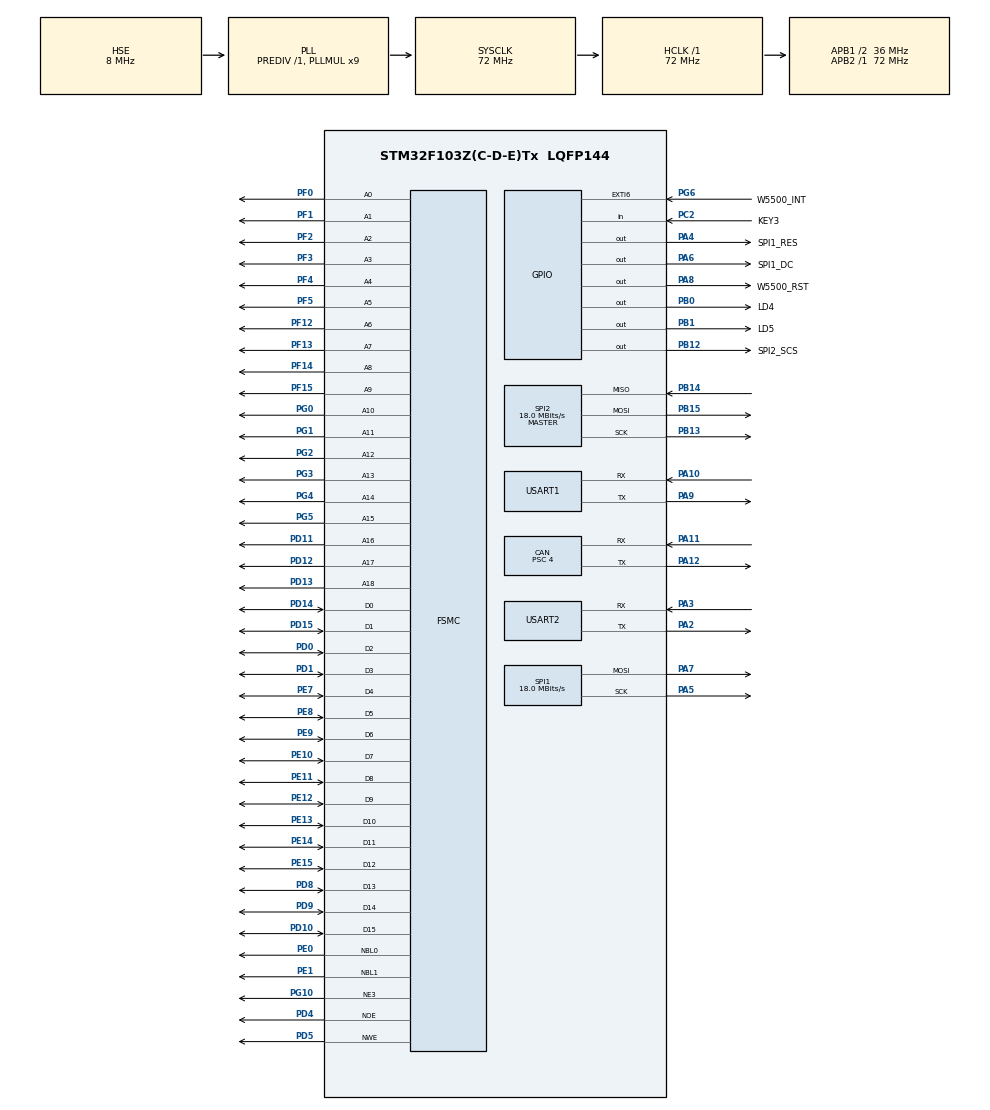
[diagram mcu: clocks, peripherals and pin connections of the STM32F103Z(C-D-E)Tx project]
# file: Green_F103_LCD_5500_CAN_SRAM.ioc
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CAN.BS1=CAN_BS1_9TQ
CAN.BS2=CAN_BS2_8TQ
CAN.CalculateTimeBit=2000
CAN.CalculateTimeQuantum=111.11111111111111
CAN.Prescaler=4
FSMC.AddressSetupTime1=0
FSMC.BusTurnAroundDuration1=0
FSMC.DataSetupTime1=4
FSMC.WriteOperation1=FSMC_WRITE_OPERATION_ENABLE
Mcu.Family=STM32F1
Mcu.Name=STM32F103Z(C-D-E)Tx
Mcu.Package=LQFP144
NVIC.PriorityGroup=NVIC_PRIORITYGROUP_4
NVIC.USART1_IRQn=true\:0\:0\:false\:false\:true\:true\:true
NVIC.USART2_IRQn=true\:0\:0\:false\:false\:true\:true\:true
OSC_IN.Mode=HSE-External-Oscillator
OSC_IN.Signal=RCC_OSC_IN
OSC_OUT.Mode=HSE-External-Oscillator
OSC_OUT.Signal=RCC_OSC_OUT
PA10.Mode=Asynchronous
PA10.Signal=USART1_RX
PA11.Mode=Master
PA11.Signal=CAN_RX
PA12.Mode=Master
PA12.Signal=CAN_TX
PA13.Mode=Serial_Wire
PA13.Signal=SYS_JTMS-SWDIO
PA14.Mode=Serial_Wire
PA14.Signal=SYS_JTCK-SWCLK
PA2.Mode=Asynchronous
PA2.Signal=USART2_TX
PA3.Mode=Asynchronous
PA3.Signal=USART2_RX
PA4.GPIO_Label=SPI1_RES
PA4.GPIO_ModeDefaultOutputPP=GPIO_MODE_OUTPUT_PP
PA4.GPIO_PuPd=GPIO_NOPULL
PA4.GPIO_Speed=GPIO_SPEED_FREQ_HIGH
PA4.PinState=GPIO_PIN_SET
PA4.Signal=GPIO_Output
PA5.Mode=TX_Only_Simplex_Unidirect_Master
PA5.Signal=SPI1_SCK
PA6.GPIO_Label=SPI1_DC
PA6.GPIO_ModeDefaultOutputPP=GPIO_MODE_OUTPUT_PP
PA6.GPIO_PuPd=GPIO_NOPULL
PA6.GPIO_Speed=GPIO_SPEED_FREQ_HIGH
PA6.PinState=GPIO_PIN_SET
PA6.Signal=GPIO_Output
PA7.Mode=TX_Only_Simplex_Unidirect_Master
PA7.Signal=SPI1_MOSI
PA8.GPIO_Label=W5500_RST
PA8.GPIO_ModeDefaultOutputPP=GPIO_MODE_OUTPUT_PP
PA8.GPIO_PuPd=GPIO_NOPULL
PA8.GPIO_Speed=GPIO_SPEED_FREQ_HIGH
PA8.PinState=GPIO_PIN_SET
PA8.Signal=GPIO_Output
PA9.Mode=Asynchronous
PA9.Signal=USART1_TX
PB0.GPIO_Label=LD4
PB0.GPIO_ModeDefaultOutputPP=GPIO_MODE_OUTPUT_PP
PB0.GPIO_PuPd=GPIO_NOPULL
PB0.GPIO_Speed=GPIO_SPEED_FREQ_HIGH
PB0.PinState=GPIO_PIN_SET
PB0.Signal=GPIO_Output
PB1.GPIO_Label=LD5
PB1.GPIO_ModeDefaultOutputPP=GPIO_MODE_OUTPUT_PP
PB1.GPIO_PuPd=GPIO_NOPULL
PB1.GPIO_Speed=GPIO_SPEED_FREQ_HIGH
PB1.PinState=GPIO_PIN_SET
PB1.Signal=GPIO_Output
PB12.GPIO_Label=SPI2_SCS
PB12.GPIO_ModeDefaultOutputPP=GPIO_MODE_OUTPUT_PP
PB12.GPIO_PuPd=GPIO_NOPULL
PB12.GPIO_Speed=GPIO_SPEED_FREQ_HIGH
PB12.PinState=GPIO_PIN_SET
PB12.Signal=GPIO_Output
PB13.Mode=Full_Duplex_Master
PB13.Signal=SPI2_SCK
PB14.Mode=Full_Duplex_Master
PB14.Signal=SPI2_MISO
PB15.Mode=Full_Duplex_Master
PB15.Signal=SPI2_MOSI
PC14-OSC32_IN.Mode=LSE-External-Oscillator
PC14-OSC32_IN.Signal=RCC_OSC32_IN
PC15-OSC32_OUT.Mode=LSE-External-Oscillator
PC15-OSC32_OUT.Signal=RCC_OSC32_OUT
PC2.GPIO_Label=KEY3
PC2.GPIO_PuPd=GPIO_PULLUP
PC2.Signal=GPIO_Input
PD0.Signal=FSMC_D2_DA2
PD1.Signal=FSMC_D3_DA3
PD10.Signal=FSMC_D15_DA15
PD11.Signal=FSMC_A16_CLE
PD12.Signal=FSMC_A17_ALE
PD13.Signal=FSMC_A18
PD14.Signal=FSMC_D0_DA0
PD15.Signal=FSMC_D1_DA1
PD4.Signal=FSMC_NOE
PD5.Signal=FSMC_NWE
PD8.Signal=FSMC_D13_DA13
PD9.Signal=FSMC_D14_DA14
PE0.Signal=FSMC_NBL0
PE1.Signal=FSMC_NBL1
PE10.Signal=FSMC_D7_DA7
PE11.Signal=FSMC_D8_DA8
PE12.Signal=FSMC_D9_DA9
PE13.Signal=FSMC_D10_DA10
PE14.Signal=FSMC_D11_DA11
PE15.Signal=FSMC_D12_DA12
PE7.Signal=FSMC_D4_DA4
PE8.Signal=FSMC_D5_DA5
PE9.Signal=FSMC_D6_DA6
PF0.Signal=FSMC_A0
PF1.Signal=FSMC_A1
PF12.Signal=FSMC_A6
PF13.Signal=FSMC_A7
PF14.Signal=FSMC_A8
PF15.Signal=FSMC_A9
PF2.Signal=FSMC_A2
PF3.Signal=FSMC_A3
PF4.Signal=FSMC_A4
PF5.Signal=FSMC_A5
PG0.Signal=FSMC_A10
PG1.Signal=FSMC_A11
PG10.Mode=NorPsramChipSelect3_1
PG10.Signal=FSMC_NE3
PG2.Signal=FSMC_A12
PG3.Signal=FSMC_A13
PG4.Signal=FSMC_A14
PG5.Signal=FSMC_A15
PG6.GPIO_Label=W5500_INT
PG6.Signal=GPXTI6
ProjectManager.HeapSize=0x800
ProjectManager.StackSize=0x800
ProjectManager.TargetToolchain=MDK-ARM V5
RCC.AHBFreq_Value=72000000
RCC.APB1CLKDivider=RCC_HCLK_DIV2
RCC.APB1Freq_Value=36000000
RCC.APB1TimFreq_Value=72000000
RCC.APB2Freq_Value=72000000
RCC.APB2TimFreq_Value=72000000
RCC.HCLKFreq_Value=72000000
RCC.PLLMUL=RCC_PLL_MUL9
RCC.PLLSourceVirtual=RCC_PLLSOURCE_HSE
RCC.SYSCLKFreq_VALUE=72000000
RCC.SYSCLKSource=RCC_SYSCLKSOURCE_PLLCLK
RCC.USBFreq_Value=72000000
SH.FSMC_A0.0=FSMC_A0,19b-a1
SH.FSMC_A1.0=FSMC_A1,19b-a1
SH.FSMC_A10.0=FSMC_A10,19b-a1
SH.FSMC_A11.0=FSMC_A11,19b-a1
SH.FSMC_A12.0=FSMC_A12,19b-a1
SH.FSMC_A13.0=FSMC_A13,19b-a1
SH.FSMC_A14.0=FSMC_A14,19b-a1
SH.FSMC_A15.0=FSMC_A15,19b-a1
SH.FSMC_A16_CLE.0=FSMC_A16,19b-a1
SH.FSMC_A17_ALE.0=FSMC_A17,19b-a1
SH.FSMC_A18.0=FSMC_A18,19b-a1
SH.FSMC_A2.0=FSMC_A2,19b-a1
SH.FSMC_A3.0=FSMC_A3,19b-a1
SH.FSMC_A4.0=FSMC_A4,19b-a1
SH.FSMC_A5.0=FSMC_A5,19b-a1
SH.FSMC_A6.0=FSMC_A6,19b-a1
SH.FSMC_A7.0=FSMC_A7,19b-a1
SH.FSMC_A8.0=FSMC_A8,19b-a1
SH.FSMC_A9.0=FSMC_A9,19b-a1
SH.FSMC_D0_DA0.0=FSMC_D0,16b-d1
SH.FSMC_D10_DA10.0=FSMC_D10,16b-d1
SH.FSMC_D11_DA11.0=FSMC_D11,16b-d1
SH.FSMC_D12_DA12.0=FSMC_D12,16b-d1
SH.FSMC_D13_DA13.0=FSMC_D13,16b-d1
SH.FSMC_D14_DA14.0=FSMC_D14,16b-d1
SH.FSMC_D15_DA15.0=FSMC_D15,16b-d1
SH.FSMC_D1_DA1.0=FSMC_D1,16b-d1
SH.FSMC_D2_DA2.0=FSMC_D2,16b-d1
SH.FSMC_D3_DA3.0=FSMC_D3,16b-d1
SH.FSMC_D4_DA4.0=FSMC_D4,16b-d1
SH.FSMC_D5_DA5.0=FSMC_D5,16b-d1
SH.FSMC_D6_DA6.0=FSMC_D6,16b-d1
SH.FSMC_D7_DA7.0=FSMC_D7,16b-d1
SH.FSMC_D8_DA8.0=FSMC_D8,16b-d1
SH.FSMC_D9_DA9.0=FSMC_D9,16b-d1
SH.FSMC_NBL0.0=FSMC_NBL0,2ByteEnable1
SH.FSMC_NBL1.0=FSMC_NBL1,2ByteEnable1
SH.FSMC_NOE.0=FSMC_NOE,Sram1
SH.FSMC_NWE.0=FSMC_NWE,Sram1
SPI1.BaudRatePrescaler=SPI_BAUDRATEPRESCALER_4
SPI1.CLKPhase=SPI_PHASE_2EDGE
SPI1.CLKPolarity=SPI_POLARITY_HIGH
SPI1.CalculateBaudRate=18.0 MBits/s
SPI1.Direction=SPI_DIRECTION_2LINES
SPI1.Mode=SPI_MODE_MASTER
SPI1.VirtualType=VM_MASTER
SPI2.CLKPhase=SPI_PHASE_2EDGE
SPI2.CLKPolarity=SPI_POLARITY_HIGH
SPI2.CalculateBaudRate=18.0 MBits/s
SPI2.Direction=SPI_DIRECTION_2LINES
SPI2.Mode=SPI_MODE_MASTER
SPI2.VirtualType=VM_MASTER
USART1.VirtualMode=VM_ASYNC
USART2.VirtualMode=VM_ASYNC
board=custom

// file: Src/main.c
/* USER CODE BEGIN Header */
/**
  ******************************************************************************
  * @file           : main.c
  * @brief          : Main program body
  ******************************************************************************
  * @attention
  *
  * <h2><center>&copy; Copyright (c) 2019 STMicroelectronics.
  * All rights reserved.</center></h2>
  *
  * This software component is licensed by ST under BSD 3-Clause license,
  * the "License"; You may not use this file except in compliance with the
  * License. You may obtain a copy of the License at:
  *                        opensource.org/licenses/BSD-3-Clause
  *
  ******************************************************************************
  */
/* USER CODE END Header */

#include "main.h"

CAN_HandleTypeDef hcan;

SPI_HandleTypeDef hspi1;
SPI_HandleTypeDef hspi2;

UART_HandleTypeDef huart1;
UART_HandleTypeDef huart2;

SRAM_HandleTypeDef hsram1;

void SystemClock_Config(void);
static void MX_GPIO_Init(void);
static void MX_CAN_Init(void);
static void MX_FSMC_Init(void);
static void MX_SPI1_Init(void);
static void MX_SPI2_Init(void);
static void MX_USART1_UART_Init(void);
static void MX_USART2_UART_Init(void);

int main(void)
{

  /* MCU Configuration--------------------------------------------------------*/

  /* Reset of all peripherals, Initializes the Flash interface and the Systick. */
  HAL_Init();

  /* Configure the system clock */
  SystemClock_Config();

  /* Initialize all configured peripherals */
  MX_GPIO_Init();
  MX_CAN_Init();
  MX_FSMC_Init();
  MX_SPI1_Init();
  MX_SPI2_Init();
  MX_USART1_UART_Init();
  MX_USART2_UART_Init();
  /* USER CODE BEGIN 2 */
  u_main();
  /* USER CODE END 2 */

  /* Infinite loop */
  while (1)
  {

  }
}

void SystemClock_Config(void)
{
  RCC_OscInitTypeDef RCC_OscInitStruct = {0};
  RCC_ClkInitTypeDef RCC_ClkInitStruct = {0};

  /** Initializes the CPU, AHB and APB busses clocks
  */
  RCC_OscInitStruct.OscillatorType = RCC_OSCILLATORTYPE_HSE;
  RCC_OscInitStruct.HSEState = RCC_HSE_ON;
  RCC_OscInitStruct.HSEPredivValue = RCC_HSE_PREDIV_DIV1;
  RCC_OscInitStruct.HSIState = RCC_HSI_ON;
  RCC_OscInitStruct.PLL.PLLState = RCC_PLL_ON;
  RCC_OscInitStruct.PLL.PLLSource = RCC_PLLSOURCE_HSE;
  RCC_OscInitStruct.PLL.PLLMUL = RCC_PLL_MUL9;
  if (HAL_RCC_OscConfig(&RCC_OscInitStruct) != HAL_OK)
  {
    Error_Handler();
  }
  /** Initializes the CPU, AHB and APB busses clocks
  */
  RCC_ClkInitStruct.ClockType = RCC_CLOCKTYPE_HCLK|RCC_CLOCKTYPE_SYSCLK
                              |RCC_CLOCKTYPE_PCLK1|RCC_CLOCKTYPE_PCLK2;
  RCC_ClkInitStruct.SYSCLKSource = RCC_SYSCLKSOURCE_PLLCLK;
  RCC_ClkInitStruct.AHBCLKDivider = RCC_SYSCLK_DIV1;
  RCC_ClkInitStruct.APB1CLKDivider = RCC_HCLK_DIV2;
  RCC_ClkInitStruct.APB2CLKDivider = RCC_HCLK_DIV1;

  if (HAL_RCC_ClockConfig(&RCC_ClkInitStruct, FLASH_LATENCY_2) != HAL_OK)
  {
    Error_Handler();
  }
}

static void MX_CAN_Init(void)
{

  hcan.Instance = CAN1;
  hcan.Init.Prescaler = 4;
  hcan.Init.Mode = CAN_MODE_NORMAL;
  hcan.Init.SyncJumpWidth = CAN_SJW_1TQ;
  hcan.Init.TimeSeg1 = CAN_BS1_9TQ;
  hcan.Init.TimeSeg2 = CAN_BS2_8TQ;
  hcan.Init.TimeTriggeredMode = DISABLE;
  hcan.Init.AutoBusOff = DISABLE;
  hcan.Init.AutoWakeUp = DISABLE;
  hcan.Init.AutoRetransmission = DISABLE;
  hcan.Init.ReceiveFifoLocked = DISABLE;
  hcan.Init.TransmitFifoPriority = DISABLE;
  if (HAL_CAN_Init(&hcan) != HAL_OK)
  {
    Error_Handler();
  }

}

static void MX_SPI1_Init(void)
{

  /* SPI1 parameter configuration*/
  hspi1.Instance = SPI1;
  hspi1.Init.Mode = SPI_MODE_MASTER;
  hspi1.Init.Direction = SPI_DIRECTION_2LINES;
  hspi1.Init.DataSize = SPI_DATASIZE_8BIT;
  hspi1.Init.CLKPolarity = SPI_POLARITY_HIGH;
  hspi1.Init.CLKPhase = SPI_PHASE_2EDGE;
  hspi1.Init.NSS = SPI_NSS_SOFT;
  hspi1.Init.BaudRatePrescaler = SPI_BAUDRATEPRESCALER_4;
  hspi1.Init.FirstBit = SPI_FIRSTBIT_MSB;
  hspi1.Init.TIMode = SPI_TIMODE_DISABLE;
  hspi1.Init.CRCCalculation = SPI_CRCCALCULATION_DISABLE;
  hspi1.Init.CRCPolynomial = 10;
  if (HAL_SPI_Init(&hspi1) != HAL_OK)
  {
    Error_Handler();
  }

}

static void MX_SPI2_Init(void)
{

  /* SPI2 parameter configuration*/
  hspi2.Instance = SPI2;
  hspi2.Init.Mode = SPI_MODE_MASTER;
  hspi2.Init.Direction = SPI_DIRECTION_2LINES;
  hspi2.Init.DataSize = SPI_DATASIZE_8BIT;
  hspi2.Init.CLKPolarity = SPI_POLARITY_HIGH;
  hspi2.Init.CLKPhase = SPI_PHASE_2EDGE;
  hspi2.Init.NSS = SPI_NSS_SOFT;
  hspi2.Init.BaudRatePrescaler = SPI_BAUDRATEPRESCALER_2;
  hspi2.Init.FirstBit = SPI_FIRSTBIT_MSB;
  hspi2.Init.TIMode = SPI_TIMODE_DISABLE;
  hspi2.Init.CRCCalculation = SPI_CRCCALCULATION_DISABLE;
  hspi2.Init.CRCPolynomial = 10;
  if (HAL_SPI_Init(&hspi2) != HAL_OK)
  {
    Error_Handler();
  }

}

static void MX_USART1_UART_Init(void)
{

  huart1.Instance = USART1;
  huart1.Init.BaudRate = 115200;
  huart1.Init.WordLength = UART_WORDLENGTH_8B;
  huart1.Init.StopBits = UART_STOPBITS_1;
  huart1.Init.Parity = UART_PARITY_NONE;
  huart1.Init.Mode = UART_MODE_TX_RX;
  huart1.Init.HwFlowCtl = UART_HWCONTROL_NONE;
  huart1.Init.OverSampling = UART_OVERSAMPLING_16;
  if (HAL_UART_Init(&huart1) != HAL_OK)
  {
    Error_Handler();
  }

}

static void MX_USART2_UART_Init(void)
{

  huart2.Instance = USART2;
  huart2.Init.BaudRate = 115200;
  huart2.Init.WordLength = UART_WORDLENGTH_8B;
  huart2.Init.StopBits = UART_STOPBITS_1;
  huart2.Init.Parity = UART_PARITY_NONE;
  huart2.Init.Mode = UART_MODE_TX_RX;
  huart2.Init.HwFlowCtl = UART_HWCONTROL_NONE;
  huart2.Init.OverSampling = UART_OVERSAMPLING_16;
  if (HAL_UART_Init(&huart2) != HAL_OK)
  {
    Error_Handler();
  }

}

static void MX_GPIO_Init(void)
{
  GPIO_InitTypeDef GPIO_InitStruct = {0};

  /* GPIO Ports Clock Enable */
  __HAL_RCC_GPIOC_CLK_ENABLE();
  __HAL_RCC_GPIOF_CLK_ENABLE();
  __HAL_RCC_GPIOA_CLK_ENABLE();
  __HAL_RCC_GPIOB_CLK_ENABLE();
  __HAL_RCC_GPIOG_CLK_ENABLE();
  __HAL_RCC_GPIOE_CLK_ENABLE();
  __HAL_RCC_GPIOD_CLK_ENABLE();

  /*Configure GPIO pin Output Level */
  HAL_GPIO_WritePin(GPIOA, SPI1_RES_Pin|SPI1_DC_Pin|W5500_RST_Pin, GPIO_PIN_SET);

  /*Configure GPIO pin Output Level */
  HAL_GPIO_WritePin(GPIOB, LD4_Pin|LD5_Pin|SPI2_SCS_Pin, GPIO_PIN_SET);

  /*Configure GPIO pin : KEY3_Pin */
  GPIO_InitStruct.Pin = KEY3_Pin;
  GPIO_InitStruct.Mode = GPIO_MODE_INPUT;
  GPIO_InitStruct.Pull = GPIO_PULLUP;
  HAL_GPIO_Init(KEY3_GPIO_Port, &GPIO_InitStruct);

  /*Configure GPIO pins : SPI1_RES_Pin SPI1_DC_Pin W5500_RST_Pin */
  GPIO_InitStruct.Pin = SPI1_RES_Pin|SPI1_DC_Pin|W5500_RST_Pin;
  GPIO_InitStruct.Mode = GPIO_MODE_OUTPUT_PP;
  GPIO_InitStruct.Pull = GPIO_NOPULL;
  GPIO_InitStruct.Speed = GPIO_SPEED_FREQ_HIGH;
  HAL_GPIO_Init(GPIOA, &GPIO_InitStruct);

  /*Configure GPIO pins : LD4_Pin LD5_Pin SPI2_SCS_Pin */
  GPIO_InitStruct.Pin = LD4_Pin|LD5_Pin|SPI2_SCS_Pin;
  GPIO_InitStruct.Mode = GPIO_MODE_OUTPUT_PP;
  GPIO_InitStruct.Pull = GPIO_NOPULL;
  GPIO_InitStruct.Speed = GPIO_SPEED_FREQ_HIGH;
  HAL_GPIO_Init(GPIOB, &GPIO_InitStruct);

  /*Configure GPIO pin : W5500_INT_Pin */
  GPIO_InitStruct.Pin = W5500_INT_Pin;
  GPIO_InitStruct.Mode = GPIO_MODE_IT_RISING;
  GPIO_InitStruct.Pull = GPIO_NOPULL;
  HAL_GPIO_Init(W5500_INT_GPIO_Port, &GPIO_InitStruct);

}

/* FSMC initialization function */
static void MX_FSMC_Init(void)
{

  FSMC_NORSRAM_TimingTypeDef Timing = {0};

  /** Perform the SRAM1 memory initialization sequence
  */
  hsram1.Instance = FSMC_NORSRAM_DEVICE;
  hsram1.Extended = FSMC_NORSRAM_EXTENDED_DEVICE;
  /* hsram1.Init */
  hsram1.Init.NSBank = FSMC_NORSRAM_BANK3;
  hsram1.Init.DataAddressMux = FSMC_DATA_ADDRESS_MUX_DISABLE;
  hsram1.Init.MemoryType = FSMC_MEMORY_TYPE_SRAM;
  hsram1.Init.MemoryDataWidth = FSMC_NORSRAM_MEM_BUS_WIDTH_16;
  hsram1.Init.BurstAccessMode = FSMC_BURST_ACCESS_MODE_DISABLE;
  hsram1.Init.WaitSignalPolarity = FSMC_WAIT_SIGNAL_POLARITY_LOW;
  hsram1.Init.WrapMode = FSMC_WRAP_MODE_DISABLE;
  hsram1.Init.WaitSignalActive = FSMC_WAIT_TIMING_BEFORE_WS;
  hsram1.Init.WriteOperation = FSMC_WRITE_OPERATION_ENABLE;
  hsram1.Init.WaitSignal = FSMC_WAIT_SIGNAL_DISABLE;
  hsram1.Init.ExtendedMode = FSMC_EXTENDED_MODE_DISABLE;
  hsram1.Init.AsynchronousWait = FSMC_ASYNCHRONOUS_WAIT_DISABLE;
  hsram1.Init.WriteBurst = FSMC_WRITE_BURST_DISABLE;
  /* Timing */
  Timing.AddressSetupTime = 0;
  Timing.AddressHoldTime = 15;
  Timing.DataSetupTime = 4;
  Timing.BusTurnAroundDuration = 0;
  Timing.CLKDivision = 16;
  Timing.DataLatency = 17;
  Timing.AccessMode = FSMC_ACCESS_MODE_A;
  /* ExtTiming */

  if (HAL_SRAM_Init(&hsram1, &Timing, NULL) != HAL_OK)
  {
    Error_Handler( );
  }

  /** Disconnect NADV
  */

  __HAL_AFIO_FSMCNADV_DISCONNECTED();

}

void Error_Handler(void)
{
}

/************************ (C) COPYRIGHT STMicroelectronics *****END OF FILE****/
